# STM32L15xxE register map
File version: 1.0
Registers are 32-bit, read-write, reset 0x0 unless marked. A register's access mark holds for its fields unless they carry their own. Offsets are from the block's base; [hi:lo] are bit positions.

## DAC — Digital-to-analog converter
Base 0x40007400
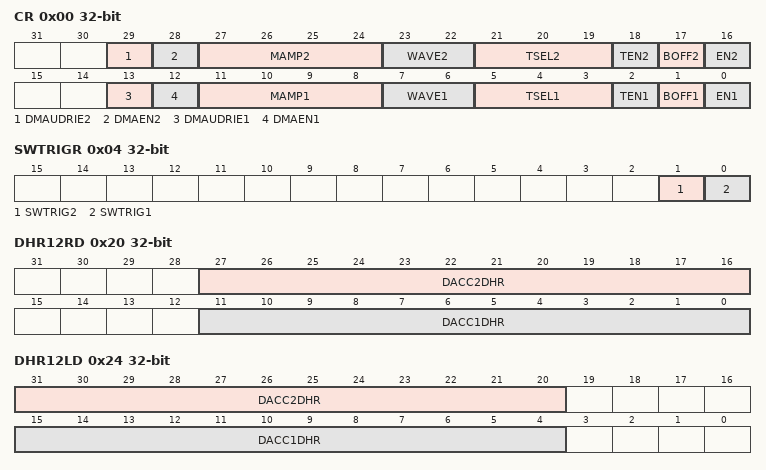
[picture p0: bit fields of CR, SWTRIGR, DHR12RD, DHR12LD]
0x00 CR — control register
  [29] DMAUDRIE2 — DAC channel2 DMA underrun interrupt enable
  [28] DMAEN2 — DAC channel2 DMA enable
  [27:24] MAMP2 — DAC channel2 mask/amplitude selector
  [23:22] WAVE2 — DAC channel2 noise/triangle wave generation enable
  [21:19] TSEL2 — DAC channel2 trigger selection
  [18] TEN2 — DAC channel2 trigger enable
  [17] BOFF2 — DAC channel2 output buffer disable
  [16] EN2 — DAC channel2 enable
  [13] DMAUDRIE1 — DAC channel1 DMA Underrun Interrupt enable
  [12] DMAEN1 — DAC channel1 DMA enable
  [11:8] MAMP1 — DAC channel1 mask/amplitude selector
  [7:6] WAVE1 — DAC channel1 noise/triangle wave generation enable
  [5:3] TSEL1 — DAC channel1 trigger selection
  [2] TEN1 — DAC channel1 trigger enable
  [1] BOFF1 — DAC channel1 output buffer disable
  [0] EN1 — DAC channel1 enable
0x04 SWTRIGR wo — software trigger register
  [1] SWTRIG2 — DAC channel2 software trigger
  [0] SWTRIG1 — DAC channel1 software trigger
0x08 DHR12R1 — channel1 12-bit right-aligned data holding register
  [11:0] DACC1DHR — DAC channel1 12-bit right-aligned data
0x0C DHR12L1 — channel1 12-bit left aligned data holding register
  [15:4] DACC1DHR — DAC channel1 12-bit left-aligned data
0x10 DHR8R1 — channel1 8-bit right aligned data holding register
  [7:0] DACC1DHR — DAC channel1 8-bit right-aligned data
0x14 DHR12R2 — channel2 12-bit right aligned data holding register
  [11:0] DACC2DHR — DAC channel2 12-bit right-aligned data
0x18 DHR12L2 — channel2 12-bit left aligned data holding register
  [15:4] DACC2DHR — DAC channel2 12-bit left-aligned data
0x1C DHR8R2 — channel2 8-bit right-aligned data holding register
  [7:0] DACC2DHR — DAC channel2 8-bit right-aligned data
0x20 DHR12RD — Dual DAC 12-bit right-aligned data holding register
  [27:16] DACC2DHR — DAC channel2 12-bit right-aligned data
  [11:0] DACC1DHR — DAC channel1 12-bit right-aligned data
0x24 DHR12LD — DUAL DAC 12-bit left aligned data holding register
  [31:20] DACC2DHR — DAC channel2 12-bit left-aligned data
  [15:4] DACC1DHR — DAC channel1 12-bit left-aligned data
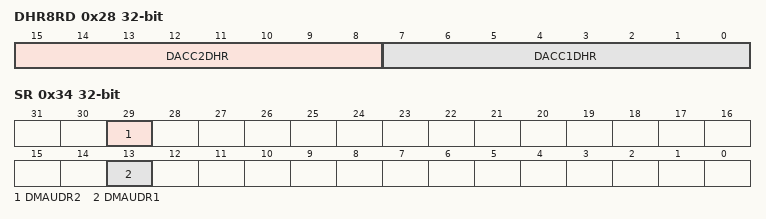
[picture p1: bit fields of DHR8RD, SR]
0x28 DHR8RD — DUAL DAC 8-bit right aligned data holding register
  [15:8] DACC2DHR — DAC channel2 8-bit right-aligned data
  [7:0] DACC1DHR — DAC channel1 8-bit right-aligned data
0x2C DOR1 ro — channel1 data output register
  [11:0] DACC1DOR — DAC channel1 data output
0x30 DOR2 ro — channel2 data output register
  [11:0] DACC2DOR — DAC channel2 data output
0x34 SR — status register
  [29] DMAUDR2 — DAC channel2 DMA underrun flag
  [13] DMAUDR1 — DAC channel1 DMA underrun flag

## EXTI — External interrupt/event controller
Base 0x40010400
0x00 IMR
  [22:0] MR — Interrupt mask on line x
0x04 EMR
  [22:0] MR — Event mask on line x
0x08 RTSR
  [22:0] TR — Rising edge trigger event configuration bit of line x
0x0C FTSR
  [22:0] TR — Falling edge trigger event configuration bit of line x
0x10 SWIER
  [22:0] SWIER — Software interrupt on line x
0x14 PR
  [22:0] PR — Pending bit

## Flash
Base 0x40023C00
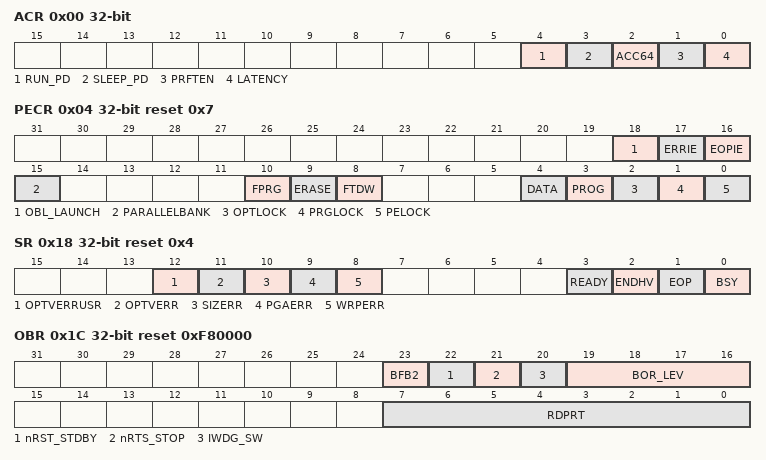
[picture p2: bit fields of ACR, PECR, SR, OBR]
0x00 ACR — Access control register
  [4] RUN_PD — Flash mode during Run
  [3] SLEEP_PD — Flash mode during Sleep
  [2] ACC64 — 64-bit access
  [1] PRFTEN — Prefetch enable
  [0] LATENCY
0x04 PECR reset 0x7 — Program/erase control register
  [18] OBL_LAUNCH — Launch the option byte loading
  [17] ERRIE — Error interrupt enable
  [16] EOPIE — End of programming interrupt enable
  [15] PARALLELBANK — Parallel bank mode
  [10] FPRG — Half Page/Double Word programming mode
  [9] ERASE — Page or Double Word erase mode
  [8] FTDW — Fixed time data write for Byte, Half Word and Word programming
  [4] DATA — Data EEPROM selection
  [3] PROG — Program memory selection
  [2] OPTLOCK — Option bytes block lock
  [1] PRGLOCK — Program memory lock
  [0] PELOCK — FLASH_PECR and data EEPROM lock
0x08 PDKEYR wo — Power down key register
  [31:0] PDKEYR — RUN_PD in FLASH_ACR key
0x0C PEKEYR wo — Program/erase key register
  [31:0] PEKEYR — FLASH_PEC and data EEPROM key
0x10 PRGKEYR wo — Program memory key register
  [31:0] PRGKEYR — Program memory key
0x14 OPTKEYR wo — Option byte key register
  [31:0] OPTKEYR — Option byte key
0x18 SR access per field reset 0x4 — Status register
  [12] OPTVERRUSR rw — Option UserValidity Error
  [11] OPTVERR rw — Option validity error
  [10] SIZERR rw — Size error
  [9] PGAERR rw — Programming alignment error
  [8] WRPERR rw — Write protected error
  [3] READY ro — Flash memory module ready after low power mode
  [2] ENDHV ro — End of high voltage
  [1] EOP ro — End of operation
  [0] BSY ro — Write/erase operations in progress
0x1C OBR ro reset 0xF80000 — Option byte register
  [23] BFB2 — Boot From Bank 2
  [22] nRST_STDBY
  [21] nRTS_STOP
  [20] IWDG_SW
  [19:16] BOR_LEV
  [7:0] RDPRT — Read protection
0x20 WRPR1 — Write protection register
  [31:0] WRP1 — Write protection
0x80 WRPR2 — Write protection register
  [31:0] WRP2
0x84 WRPR3 — Write protection register
  [31:0] WRP3
